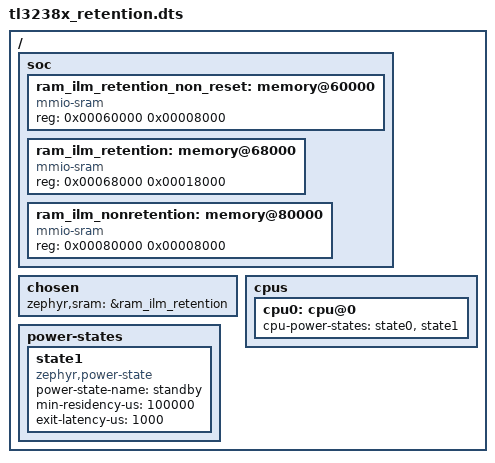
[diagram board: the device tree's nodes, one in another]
/*
 * Copyright (c) 2025 Telink Semiconductor
 *
 * SPDX-License-Identifier: Apache-2.0
 */

/dts-v1/;

#include "tl3238x-common.dtsi"

/ {
	soc {
		/delete-node/ memory@60000;
		/delete-node/ memory@68000;
		/delete-node/ memory@80000;

		ram_ilm_retention_non_reset: memory@60000 {
			compatible = "mmio-sram";
		};

		ram_ilm_retention: memory@68000 {
			compatible = "mmio-sram";
		};

		ram_ilm_nonretention: memory@80000 {
			compatible = "mmio-sram";
		};
	};

	chosen {
		zephyr,sram = &ram_ilm_retention;
	};

	cpus {
		cpu0: cpu@0 {
			cpu-power-states = <&state0 &state1>;
		};
	};

	power-states {
		state1: state1 {
			compatible = "zephyr,power-state";
			power-state-name = "standby";
			min-residency-us = <100000>;
			exit-latency-us = <1000>;
		};
	};
};
&ram_ilm_retention_non_reset {
	reg = <0x00060000 0x00008000>;
};

&ram_ilm_retention {
	reg = <0x00068000 0x00018000>;
};

&ram_ilm_nonretention {
	reg = <0x00080000 0x00008000>;
};
